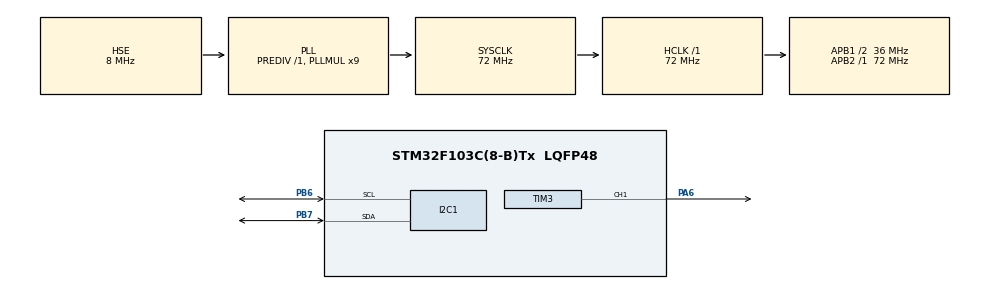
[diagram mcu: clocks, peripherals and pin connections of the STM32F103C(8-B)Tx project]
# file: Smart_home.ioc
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Mcu.Family=STM32F1
Mcu.Name=STM32F103C(8-B)Tx
Mcu.Package=LQFP48
NVIC.PriorityGroup=NVIC_PRIORITYGROUP_4
PA13.Mode=Serial_Wire
PA13.Signal=SYS_JTMS-SWDIO
PA14.Mode=Serial_Wire
PA14.Signal=SYS_JTCK-SWCLK
PA6.Signal=S_TIM3_CH1
PB6.Mode=I2C
PB6.Signal=I2C1_SCL
PB7.Mode=I2C
PB7.Signal=I2C1_SDA
PC14-OSC32_IN.Mode=LSE-External-Oscillator
PC14-OSC32_IN.Signal=RCC_OSC32_IN
PC15-OSC32_OUT.Mode=LSE-External-Oscillator
PC15-OSC32_OUT.Signal=RCC_OSC32_OUT
PD0-OSC_IN.Mode=HSE-External-Oscillator
PD0-OSC_IN.Signal=RCC_OSC_IN
PD1-OSC_OUT.Mode=HSE-External-Oscillator
PD1-OSC_OUT.Signal=RCC_OSC_OUT
ProjectManager.HeapSize=0x200
ProjectManager.StackSize=0x400
ProjectManager.TargetToolchain=SW4STM32
RCC.AHBFreq_Value=72000000
RCC.APB1CLKDivider=RCC_HCLK_DIV2
RCC.APB1Freq_Value=36000000
RCC.APB1TimFreq_Value=72000000
RCC.APB2Freq_Value=72000000
RCC.APB2TimFreq_Value=72000000
RCC.HCLKFreq_Value=72000000
RCC.PLLMUL=RCC_PLL_MUL9
RCC.PLLSourceVirtual=RCC_PLLSOURCE_HSE
RCC.SYSCLKFreq_VALUE=72000000
RCC.SYSCLKSource=RCC_SYSCLKSOURCE_PLLCLK
RCC.USBFreq_Value=72000000
SH.S_TIM3_CH1.0=TIM3_CH1,PWM Generation1 CH1
TIM1.Prescaler=71
TIM3.Channel-PWM\ Generation1\ CH1=TIM_CHANNEL_1
TIM3.OCPolarity_1=TIM_OCPOLARITY_LOW
TIM3.Period=499
TIM3.Prescaler=71
VP_TIM1_VS_ClockSourceINT.Mode=Internal
VP_TIM3_VS_ClockSourceINT.Mode=Internal
board=custom

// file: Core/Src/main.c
/* USER CODE BEGIN Header */
/**
  ******************************************************************************
  * @file           : main.c
  * @brief          : Main program body
  ******************************************************************************
  * @attention
  *
  * <h2><center>&copy; Copyright (c) 2024 STMicroelectronics.
  * All rights reserved.</center></h2>
  *
  * This software component is licensed by ST under BSD 3-Clause license,
  * the "License"; You may not use this file except in compliance with the
  * License. You may obtain a copy of the License at:
  *                        opensource.org/licenses/BSD-3-Clause
  *
  ******************************************************************************
  */
/* USER CODE END Header */
#include "main.h"
#include "i2c.h"
#include "tim.h"
#include "gpio.h"

/* USER CODE BEGIN Includes */
#include "oled.h"
#include "dht11.h"
/* USER CODE END Includes */

void SystemClock_Config(void);

/* USER CODE BEGIN 0 */
extern uint8_t Data[5];
//Gets the number of digits in decimal for each element in Data[].
int getDecimalDigits(uint8_t num)
{
    int count = 0;

    while (num > 0)
    {
        num /= 10;
        count++;
    }

    return count;
}
//Displays temperature and humidity
void dht_oled()
{
    if(DHT_Read())
    {
        OLED_ShowCHinese(0,0,8);//"shi"
        OLED_ShowCHinese(16,0,10);//"du"
        OLED_ShowChar(32,0,26+' ',16);//":"
        OLED_ShowNum(40,0,(unsigned int)Data[0],getDecimalDigits(Data[0]),16);//Humidity values in single digits and tens of digits
        OLED_ShowChar(40+getDecimalDigits(Data[0])*8,0,5+' ',16);//"%"
        //printf("H:%.1f%%,T:%.fC\r\n",Data[0]+0.1*Data[1],Data[2]+0.1*Data[3]);
        OLED_ShowCHinese(0,2,9);//"wen"
        OLED_ShowCHinese(16,2,10);//"du"
        OLED_ShowChar(32,2,26+' ',16);//":"
        OLED_ShowNum(40,2,(unsigned int)Data[2],getDecimalDigits(Data[2]),16);//Temperature values in single digits and tens
        OLED_ShowChar(40+getDecimalDigits(Data[2])*8,2,14+' ',16);//"."
        OLED_ShowNum(40+(getDecimalDigits(Data[2])+1)*8,2,(unsigned int)Data[3],getDecimalDigits(Data[3]),16);//The decimal place of the temperature value
        OLED_ShowChar(40+(getDecimalDigits(Data[2])+getDecimalDigits(Data[3])+1)*8,2,35+' ',16);//"C"
    }
    HAL_Delay(50);
}
/* USER CODE END 0 */

int main(void)
{

  /* MCU Configuration--------------------------------------------------------*/

  /* Reset of all peripherals, Initializes the Flash interface and the Systick. */
  HAL_Init();

  /* Configure the system clock */
  SystemClock_Config();

  /* Initialize all configured peripherals */
  MX_GPIO_Init();
  MX_I2C1_Init();
  MX_TIM1_Init();
  MX_TIM3_Init();
  /* USER CODE BEGIN 2 */
  uint16_t pwmVal=500;//The higher the value,the dimmer the headlight
  OLED_Init();
  OLED_Clear();
  OLED_ShowCHinese(32,0,0);//"bi"
  OLED_ShowCHinese(48,0,1);//"ye"
  OLED_ShowCHinese(64,0,2);//"she"
  OLED_ShowCHinese(80,0,3);//"ji"
  OLED_ShowNum(24,2,3120002342,10,16);//"3120002342"
  OLED_ShowCHinese(32,4,4);//"zhi"
  OLED_ShowCHinese(48,4,5);//"neng"
  OLED_ShowCHinese(64,4,6);//"jia"
  OLED_ShowCHinese(80,4,7);//"ju"
  HAL_Delay(1000);
  OLED_Clear();
  HAL_TIM_PWM_Start(&htim3,TIM_CHANNEL_1);
  //__HAL_TIM_SET_COMPARE(&htim3,TIM_CHANNEL_1,pwmVal);
  /* USER CODE END 2 */

  /* Infinite loop */
  while (1)
  {

    /* USER CODE BEGIN 3 */
      dht_oled();
      while(pwmVal){
          pwmVal--;
          __HAL_TIM_SET_COMPARE(&htim3,TIM_CHANNEL_1,pwmVal);
          HAL_Delay(5);
      }
      while (pwmVal<500){
          pwmVal++;
          __HAL_TIM_SET_COMPARE(&htim3,TIM_CHANNEL_1,pwmVal);
          HAL_Delay(5);
      }
      HAL_Delay(100);
  }
  /* USER CODE END 3 */
}

void SystemClock_Config(void)
{
  RCC_OscInitTypeDef RCC_OscInitStruct = {0};
  RCC_ClkInitTypeDef RCC_ClkInitStruct = {0};

  /** Initializes the RCC Oscillators according to the specified parameters
  * in the RCC_OscInitTypeDef structure.
  */
  RCC_OscInitStruct.OscillatorType = RCC_OSCILLATORTYPE_HSE;
  RCC_OscInitStruct.HSEState = RCC_HSE_ON;
  RCC_OscInitStruct.HSEPredivValue = RCC_HSE_PREDIV_DIV1;
  RCC_OscInitStruct.HSIState = RCC_HSI_ON;
  RCC_OscInitStruct.PLL.PLLState = RCC_PLL_ON;
  RCC_OscInitStruct.PLL.PLLSource = RCC_PLLSOURCE_HSE;
  RCC_OscInitStruct.PLL.PLLMUL = RCC_PLL_MUL9;
  if (HAL_RCC_OscConfig(&RCC_OscInitStruct) != HAL_OK)
  {
    Error_Handler();
  }
  /** Initializes the CPU, AHB and APB buses clocks
  */
  RCC_ClkInitStruct.ClockType = RCC_CLOCKTYPE_HCLK|RCC_CLOCKTYPE_SYSCLK
                              |RCC_CLOCKTYPE_PCLK1|RCC_CLOCKTYPE_PCLK2;
  RCC_ClkInitStruct.SYSCLKSource = RCC_SYSCLKSOURCE_PLLCLK;
  RCC_ClkInitStruct.AHBCLKDivider = RCC_SYSCLK_DIV1;
  RCC_ClkInitStruct.APB1CLKDivider = RCC_HCLK_DIV2;
  RCC_ClkInitStruct.APB2CLKDivider = RCC_HCLK_DIV1;

  if (HAL_RCC_ClockConfig(&RCC_ClkInitStruct, FLASH_LATENCY_2) != HAL_OK)
  {
    Error_Handler();
  }
}

void Error_Handler(void)
{
  __disable_irq();
  while (1)
  {
  }
}

/************************ (C) COPYRIGHT STMicroelectronics *****END OF FILE****/
